# WBZ450 register map
Vendor: Microchip
Registers are 32-bit, read-write, reset 0x0 unless marked. A register's access mark holds for its fields unless they carry their own. Addresses are absolute, and some are shared; only a register's first bit layout is shown; [hi:lo] are bit positions; {n}, {i} and the like mark numbered series.

## CMCC
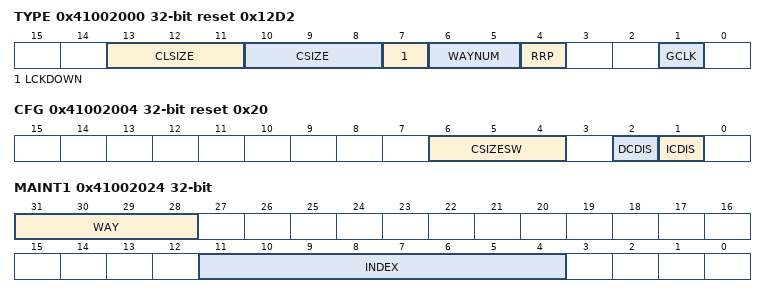
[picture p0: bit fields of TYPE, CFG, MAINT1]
0x41002000 TYPE ro reset 0x12D2
  [13:11] CLSIZE — Cache Line Size
    0=CLSIZE_4B (Cache Line Size is 4 bytes); 1=CLSIZE_8B (Cache Line Size is 8 bytes); 2=CLSIZE_16B (Cache Line Size is 16 bytes); 3=CLSIZE_32B (Cache Line Size is 32 bytes); 4=CLSIZE_64B (Cache Line Size is 64 bytes); 5=CLSIZE_128B (Cache Line Size is 128 bytes)
  [10:8] CSIZE — Cache Size
    0=CSIZE_1KB (Cache Size is 1 KB); 1=CSIZE_2KB (Cache Size is 2 KB); 2=CSIZE_4KB (Cache Size is 4 KB); 3=CSIZE_8KB (Cache Size is 8 KB); 4=CSIZE_16KB (Cache Size is 16 KB); 5=CSIZE_32KB (Cache Size is 32 KB); 6=CSIZE_64KB (Cache Size is 64 KB)
  [7] LCKDOWN — Lock Down supported
  [6:5] WAYNUM — Number of Way
    0=DMAPPED (Direct Mapped Cache); 1=ARCH2WAY (2-WAY set associative); 2=ARCH4WAY (4-WAY set associative)
  [4] RRP — Round Robin Policy supported
  [1] GCLK — dynamic Clock Gating supported
0x41002004 CFG reset 0x20
  [6:4] CSIZESW — Cache size configured by software
    0=CONF_CSIZE_1KB (The Cache Size is configured to 1KB); 1=CONF_CSIZE_2KB (The Cache Size is configured to 2KB); 2=CONF_CSIZE_4KB (The Cache Size is configured to 4KB); 3=CONF_CSIZE_8KB (The Cache Size is configured to 8KB); 4=CONF_CSIZE_16KB (The Cache Size is configured to 16KB); 5=CONF_CSIZE_32KB (The Cache Size is configured to 32KB); 6=CONF_CSIZE_64KB (The Cache Size is configured to 64KB)
  [2] DCDIS — Data Cache Disable
  [1] ICDIS — Instruction Cache Disable
0x41002008 CTRL wo
  [0] CEN — Cache Controller Enable
0x4100200C SR ro
  [0] CSTS — Cache Controller Status
0x41002010 LCKWAY
  [3:0] LCKWAY — Lockdown way Register
0x41002020 MAINT0 wo
  [0] INVALL — Cache Controller invalidate All
0x41002024 MAINT1 wo
  [31:28] WAY — Invalidate Way
    {v}=Way {v} is selection for index invalidation (v=0..3)
  [11:4] INDEX — Invalidate Index
0x41002028 MCFG
  [1:0] MODE — Cache Controller Monitor Counter Mode
    0=CYCLE_COUNT (Cycle counter); 1=IHIT_COUNT (Instruction hit counter); 2=DHIT_COUNT (Data hit counter)
0x4100202C MEN
  [0] MENABLE — Cache Controller Monitor Enable
0x41002030 MCTRL wo
  [0] SWRST — Cache Controller Software Reset
0x41002034 MSR ro
  [31:0] EVENT_CNT — Monitor Event Counter

## EVSYS
0x41006000 CTRLA 8-bit
  [0] SWRST — Software Reset
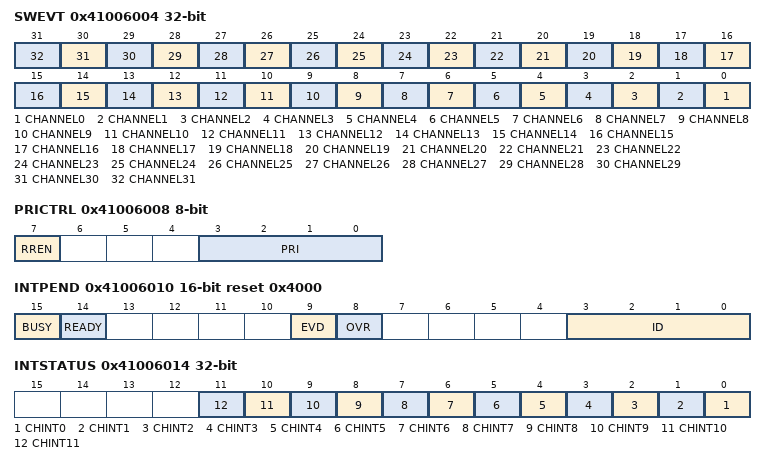
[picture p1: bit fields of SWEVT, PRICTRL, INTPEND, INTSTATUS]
0x41006004 SWEVT wo
  [n] CHANNEL{n} (n=0..31) — Channel {n} Software Selection
0x41006008 PRICTRL 8-bit
  [7] RREN — Round-Robin Scheduling Enable
  [3:0] PRI — Channel Priority Number
0x41006010 INTPEND 16-bit reset 0x4000
  [15] BUSY
  [14] READY
  [9] EVD — Channel Event Detected
  [8] OVR — Channel Overrun
  [3:0] ID — Channel ID
0x41006014 INTSTATUS ro
  [n] CHINT{n} (n=0..11) — Channel {n} Pending Interrupt
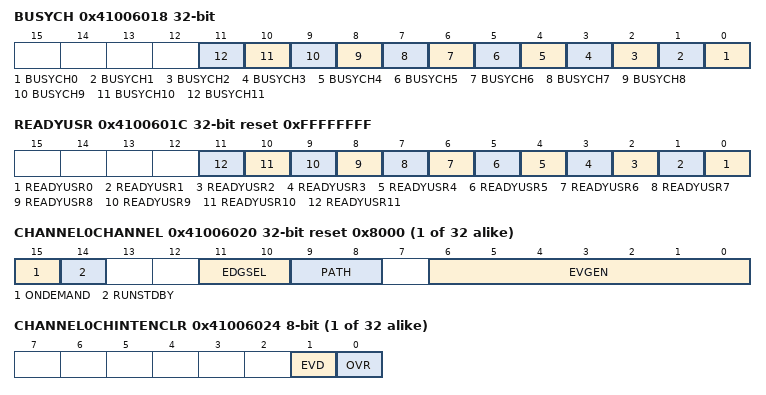
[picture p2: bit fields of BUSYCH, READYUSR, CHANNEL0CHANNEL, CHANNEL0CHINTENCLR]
0x41006018 BUSYCH ro
  [n] BUSYCH{n} (n=0..11) — Busy Channel {n}
0x4100601C READYUSR ro reset 0xFFFFFFFF
  [n] READYUSR{n} (n=0..11) — Ready User for Channel {n}
{0x41006020+8i} CHANNEL{i}CHANNEL reset 0x8000 (i=0..31)
  [15] ONDEMAND — Generic Clock On Demand
  [14] RUNSTDBY — Run in standby
  [11:10] EDGSEL — Edge Detection Selection
    0=NO_EVT_OUTPUT (No event output when using the resynchronized or synchronous path); 1=RISING_EDGE (Event detection only on the rising edge of the signal from the event generator when using the resynchronized or synchronous path); 2=FALLING_EDGE (Event detection only on the falling edge of the signal from the event generator when using the resynchronized or synchronous path); 3=BOTH_EDGES (Event detection on rising and falling edges of the signal from the event generator when using the resynchronized or synchronous path)
  [9:8] PATH — Path Selection
    0=SYNCHRONOUS (Synchronous path); 1=RESYNCHRONIZED (Resynchronized path); 2=ASYNCHRONOUS (Asynchronous path)
  [6:0] EVGEN — Event Generator Selection
{0x41006024+8i} CHANNEL{i}CHINTENCLR 8-bit (i=0..31)
  [1] EVD — Channel Event Detected Interrupt Disable
  [0] OVR — Channel Overrun Interrupt Disable
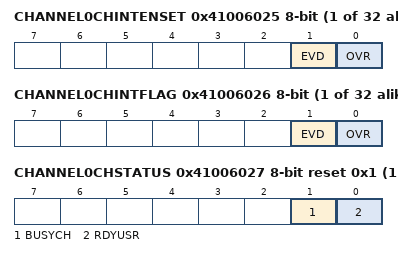
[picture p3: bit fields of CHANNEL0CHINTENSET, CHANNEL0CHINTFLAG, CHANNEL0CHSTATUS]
{0x41006025+8i} CHANNEL{i}CHINTENSET 8-bit (i=0..31)
  [1] EVD — Channel Event Detected Interrupt Enable
  [0] OVR — Channel Overrun Interrupt Enable
{0x41006026+8i} CHANNEL{i}CHINTFLAG 8-bit (i=0..31)
  [1] EVD — Channel Event Detected
  [0] OVR — Channel Overrun
{0x41006027+8i} CHANNEL{i}CHSTATUS 8-bit ro reset 0x1 (i=0..31)
  [1] BUSYCH — Busy Channel
  [0] RDYUSR — Ready User
{0x41006120+4i} USER{i} (i=0..51)
  [5:0] CHANNEL — Channel Event Selection
